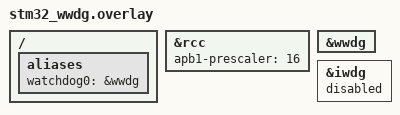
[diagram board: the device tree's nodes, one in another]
/*
 * Copyright (c) 2021 Thomas Stranger
 *
 * SPDX-License-Identifier: Apache-2.0
 */

/ {
	aliases {
		watchdog0 = &wwdg;
	};
};

&rcc {
	apb1-prescaler = <16>;
};

&wwdg {
	status = "okay";
};

&iwdg {
	status = "disabled";
};
